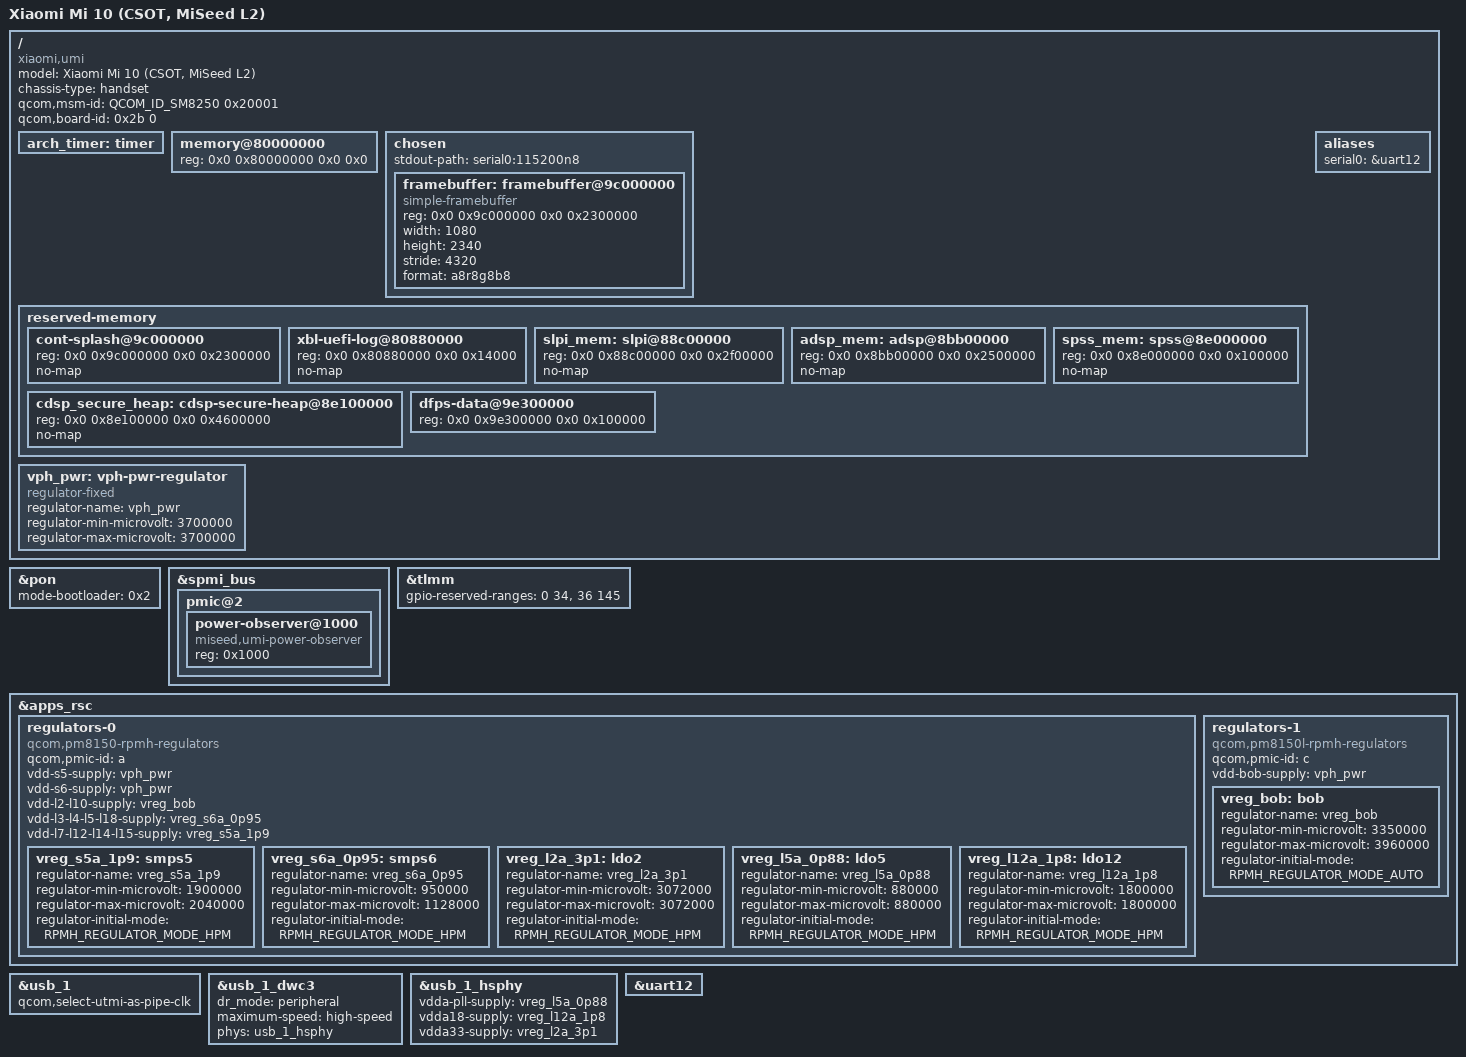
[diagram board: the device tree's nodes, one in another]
// SPDX-License-Identifier: BSD-3-Clause
/*
 * MiSeed's first board build target for Xiaomi Mi 10 (umi, CSOT reference).
 * The board ID and inherited ABL framebuffer are from the tested upstream
 * headless boot reference at misaka-link/umi-linux@cf83073887899f485a5c606f9842c5e691ea796c.
 * They are reference inputs, not measurements from this MiSeed device.
 */
/dts-v1/;

#include <dt-bindings/arm/qcom,ids.h>
#include <dt-bindings/regulator/qcom,rpmh-regulator.h>
#include "sm8250.dtsi"
#include "pm8150.dtsi"
#include "pm8150b.dtsi"
#include "pm8150l.dtsi"
#include "pm8009.dtsi"
#include "umi-pm8150b.dtsi"
#include "umi-pps.dtsi"

/* The SM8250 MTP defaults do not match the Umi remote-processor carveouts. */
/delete-node/ &adsp_mem;
/delete-node/ &cdsp_secure_heap;
/delete-node/ &slpi_mem;
/delete-node/ &spss_mem;

/ {
	model = "Xiaomi Mi 10 (CSOT, MiSeed L2)";
	compatible = "xiaomi,umi", "qcom,sm8250";
	chassis-type = "handset";
	qcom,msm-id = <QCOM_ID_SM8250 0x20001>;
	qcom,board-id = <0x2b 0>;

	/* ABL's stock overlay expects this alias for the ARM architectural timer. */
	arch_timer: timer { };

	/* ABL is expected to fill the zero-sized RAM range from its memory map. */
	memory@80000000 {
		device_type = "memory";
		reg = <0x0 0x80000000 0x0 0x0>;
	};

	chosen {
		#address-cells = <2>;
		#size-cells = <2>;
		ranges;
		stdout-path = "serial0:115200n8";

		framebuffer: framebuffer@9c000000 {
			compatible = "simple-framebuffer";
			reg = <0x0 0x9c000000 0x0 0x2300000>;
			width = <1080>;
			height = <2340>;
			stride = <4320>;
			format = "a8r8g8b8";
		};
	};

	/* Keep the inherited ABL splash buffer out of the Linux allocator. */
	reserved-memory {
		#address-cells = <2>;
		#size-cells = <2>;
		ranges;

		cont-splash@9c000000 {
			reg = <0x0 0x9c000000 0x0 0x2300000>;
			no-map;
		};

		/* Match the Umi regions in the official LOS DTB. */
		xbl-uefi-log@80880000 {
			reg = <0x0 0x80880000 0x0 0x14000>;
			no-map;
		};

		slpi_mem: slpi@88c00000 {
			reg = <0x0 0x88c00000 0x0 0x2f00000>;
			no-map;
		};

		adsp_mem: adsp@8bb00000 {
			reg = <0x0 0x8bb00000 0x0 0x2500000>;
			no-map;
		};

		spss_mem: spss@8e000000 {
			reg = <0x0 0x8e000000 0x0 0x100000>;
			no-map;
		};

		cdsp_secure_heap: cdsp-secure-heap@8e100000 {
			reg = <0x0 0x8e100000 0x0 0x4600000>;
			no-map;
		};

		/* Umi's firmware-owned display frame-rate data area. */
		dfps-data@9e300000 {
			reg = <0x0 0x9e300000 0x0 0x100000>;
		};
	};

	vph_pwr: vph-pwr-regulator {
		compatible = "regulator-fixed";
		regulator-name = "vph_pwr";
		regulator-min-microvolt = <3700000>;
		regulator-max-microvolt = <3700000>;
	};

	#include "umi-csot-abl-anchors.dtsi"
};

/* Match Qualcomm Xiaomi SM8250 PON bootloader-reboot convention. */
&pon {
	mode-bootloader = <0x2>;
};

/* Diagnostic status reads only; this node never initializes/enables charging. */
&spmi_bus {
	pmic@2 {
		power-observer@1000 {
			compatible = "miseed,umi-power-observer";
			reg = <0x1000>;
		};
	};
};

/* First TLMM profile: only the existing UART12 pins (SOUTH 34/35).
 * Both pinned Umi mainline references leave these pins unreserved. Reserve
 * everything else, including disputed NORTH GPIO8/68 and unused I2C15 44/45.
 * This is a minimal consumer allowlist, not a claim that other pins are bad.
 * No power-path GPIO is requested by this profile. Requires fresh boot L3.
 */
&tlmm {
	gpio-reserved-ranges = <0 34>, <36 145>;
	status = "okay";
};

/* USB PHY PMIC rails, selectively adapted from the pinned Umi board DTS. */
&apps_rsc {
	regulators-0 {
		compatible = "qcom,pm8150-rpmh-regulators";
		qcom,pmic-id = "a";
		vdd-s5-supply = <&vph_pwr>;
		vdd-s6-supply = <&vph_pwr>;
		vdd-l2-l10-supply = <&vreg_bob>;
		vdd-l3-l4-l5-l18-supply = <&vreg_s6a_0p95>;
		vdd-l7-l12-l14-l15-supply = <&vreg_s5a_1p9>;

		vreg_s5a_1p9: smps5 {
			regulator-name = "vreg_s5a_1p9";
			regulator-min-microvolt = <1900000>;
			regulator-max-microvolt = <2040000>;
			regulator-initial-mode = <RPMH_REGULATOR_MODE_HPM>;
		};

		vreg_s6a_0p95: smps6 {
			regulator-name = "vreg_s6a_0p95";
			regulator-min-microvolt = <950000>;
			regulator-max-microvolt = <1128000>;
			regulator-initial-mode = <RPMH_REGULATOR_MODE_HPM>;
		};

		vreg_l2a_3p1: ldo2 {
			regulator-name = "vreg_l2a_3p1";
			regulator-min-microvolt = <3072000>;
			regulator-max-microvolt = <3072000>;
			regulator-initial-mode = <RPMH_REGULATOR_MODE_HPM>;
		};

		vreg_l5a_0p88: ldo5 {
			regulator-name = "vreg_l5a_0p88";
			regulator-min-microvolt = <880000>;
			regulator-max-microvolt = <880000>;
			regulator-initial-mode = <RPMH_REGULATOR_MODE_HPM>;
		};

		vreg_l12a_1p8: ldo12 {
			regulator-name = "vreg_l12a_1p8";
			regulator-min-microvolt = <1800000>;
			regulator-max-microvolt = <1800000>;
			regulator-initial-mode = <RPMH_REGULATOR_MODE_HPM>;
		};
	};

	regulators-1 {
		compatible = "qcom,pm8150l-rpmh-regulators";
		qcom,pmic-id = "c";
		vdd-bob-supply = <&vph_pwr>;

		vreg_bob: bob {
			regulator-name = "vreg_bob";
			regulator-min-microvolt = <3350000>;
			regulator-max-microvolt = <3960000>;
			regulator-initial-mode = <RPMH_REGULATOR_MODE_AUTO>;
		};
	};
};

/*
 * USB device mode and UART12 values are adapted from
 * colorgarden/umi-mainline@5fa2e0048f89b82355d2a9de89c1d74ab9910959
 * (DTS SPDX BSD-3-Clause). The USB PHY rail voltage limits are checked
 * against both that Umi DTS and the official LineageOS 23.2 device DTB.
 */

/ {
	aliases {
		serial0 = &uart12;
	};
};

&usb_1 {
	qcom,select-utmi-as-pipe-clk;
	status = "okay";
};

&usb_1_dwc3 {
	dr_mode = "peripheral";
	maximum-speed = "high-speed";
	phys = <&usb_1_hsphy>;
	phy-names = "usb2-phy";
	status = "okay";
};

&usb_1_hsphy {
	vdda-pll-supply = <&vreg_l5a_0p88>;
	vdda18-supply = <&vreg_l12a_1p8>;
	vdda33-supply = <&vreg_l2a_3p1>;
	status = "okay";
};

&uart12 {
	status = "okay";
};
